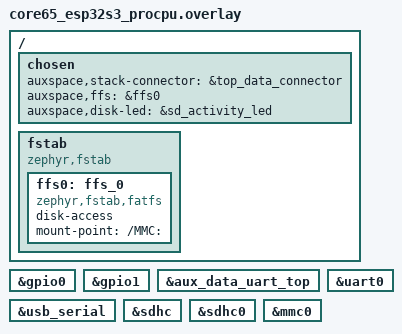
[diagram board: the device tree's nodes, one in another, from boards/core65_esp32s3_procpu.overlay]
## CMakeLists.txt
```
#-------------------------------------------------------------------------------
# telemetry_logger - AUX-Core ground-side telemetry recorder
#
# Copyright (c) 2026 Auxspace e.V.
# SPDX-License-Identifier: Apache-2.0

cmake_minimum_required(VERSION 3.20.0)

find_package(Zephyr REQUIRED HINTS $ENV{ZEPHYR_BASE})

project(telemetry_logger LANGUAGES C)

target_sources(app PRIVATE
	src/main.c
	src/link.c
	src/recorder.c
	)

target_sources_ifdef(CONFIG_TELEMETRY_LOGGER_SHELL app PRIVATE
	src/tlog_shell.c
	)
```

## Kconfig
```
# Copyright (c) 2026 Auxspace e.V.
# SPDX-License-Identifier: Apache-2.0
#
# Application Kconfig entry point for telemetry_logger, the AUX-Core
# ground-side recorder for frames delivered by an abby receiver.

menu "Zephyr"

source "Kconfig.zephyr"

endmenu

module = TELEMETRY_LOGGER
module-str = TELEMETRY_LOGGER
source "subsys/logging/Kconfig.template.log_config"

menu "telemetry_logger - ground-side telemetry recorder"

menu "Stack link"

config TELEMETRY_LOGGER_RX_RING_SIZE
	int "Receive ring buffer size (bytes)"
	default 1024
	help
	  Buffers bytes between the UART interrupt and the frame parser.
	  Overruns are counted and reported by "tlog status".

config TELEMETRY_LOGGER_LINK_STACK_SIZE
	int "Link parser thread stack size (bytes)"
	default 2048

config TELEMETRY_LOGGER_LINK_THREAD_PRIORITY
	int "Link parser thread priority"
	default 7
	help
	  Above the recorder thread, so parsing keeps up with the UART
	  while the SD card stalls on a write or a sync.

endmenu # Stack link

menu "Recorder"

config TELEMETRY_LOGGER_DIR
	string "Directory the recordings are written to"
	default "/MMC:/RX"
	help
	  Created if missing. Each recording session gets the next free
	  index in here: RX_<n>.BIN holds the frames verbatim, RX_<n>.CSV
	  the decoded rows.

config TELEMETRY_LOGGER_CSV
	bool "Also write a decoded CSV next to the raw recording"
	default y
	select REQUIRES_FLOAT_PRINTF
	help
	  One row per frame with the receive time and the SM_UPDATE /
	  STATUS fields decoded. The .BIN file is the authoritative
	  record either way; the CSV only saves a decoding step when
	  reading the card on a laptop.

config TELEMETRY_LOGGER_QUEUE_DEPTH
	int "Frames buffered between the parser and the SD card"
	default 16
	range 2 256
	help
	  Each slot holds one maximum-size frame (~270 bytes). At the
	  brain board's 2 Hz downlink 16 slots ride out an 8 s card
	  stall. Frames that find the queue full are counted as dropped.

config TELEMETRY_LOGGER_SYNC_INTERVAL_MS
	int "Maximum time between file syncs (ms)"
	default 1000
	range 100 60000
	help
	  Bounds how much of the recording a power cut can take with it.
	  FAT only commits the directory entry's size on sync, so data
	  written after the last sync is lost on a hard power-off.

config TELEMETRY_LOGGER_RETRY_MS
	int "Retry interval while no recording is open (ms)"
	default 2000
	range 100 60000
	help
	  With no card, an unformatted card or after a write error the
	  recorder re-mounts and opens a fresh recording at this interval,
	  so a card inserted after boot is picked up without a reset.

config TELEMETRY_LOGGER_WRITER_STACK_SIZE
	int "Recorder thread stack size (bytes)"
	default 4096

config TELEMETRY_LOGGER_WRITER_THREAD_PRIORITY
	int "Recorder thread priority"
	default 9

endmenu # Recorder

config TELEMETRY_LOGGER_HEARTBEAT_SEC
	int "Heartbeat interval (s)"
	default 30
	range 1 3600

config TELEMETRY_LOGGER_HEARTBEAT_LOG
	bool "Log counters on each heartbeat"
	default y

config TELEMETRY_LOGGER_SHELL
	bool "tlog shell commands"
	depends on SHELL
	default y if SHELL
	help
	  Registers the "tlog" command tree: status, and test to record a
	  synthetic frame so the SD path can be proven without a receiver
	  attached.

endmenu
```

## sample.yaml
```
# Copyright (c) 2026 Auxspace e.V.
# SPDX-License-Identifier: Apache-2.0
#
# Lets Twister build the application in CI. Build checks only: proving the
# recorder end to end needs an abby receiver and an SD card.
sample:
  description: AUX-Core recorder for telemetry frames from an abby receiver
  name: telemetry_logger
common:
  build_only: true
  platform_allow:
    - core65@1/esp32s3/procpu
  integration_platforms:
    - core65@1/esp32s3/procpu
tests:
  telemetry_logger.default.sysbuild:
    sysbuild: true
  telemetry_logger.debug.sysbuild:
    sysbuild: true
    extra_overlay_confs:
      - debug.conf
  telemetry_logger.no_csv:
    extra_configs:
      - CONFIG_TELEMETRY_LOGGER_CSV=n
  telemetry_logger.no_shell:
    extra_configs:
      - CONFIG_SHELL=n
      - CONFIG_TELEMETRY_LOGGER_SHELL=n
      - CONFIG_FILE_SYSTEM_SHELL=n
```

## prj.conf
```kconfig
# Copyright (c) 2026 Auxspace e.V.
# SPDX-License-Identifier: Apache-2.0

CONFIG_BOOT_BANNER_STRING="Booting AURORA"

CONFIG_LOG=y
CONFIG_LOG_DEFAULT_LEVEL=3

CONFIG_CONSOLE=y
CONFIG_SERIAL=y

# The stack-link receiver drains the UART from its interrupt.
CONFIG_UART_INTERRUPT_DRIVEN=y

CONFIG_CRC=y

CONFIG_FILE_SYSTEM=y

# Bring-up shell: "tlog status", "tlog test", and "fs" to pull recordings
# off the card without removing it.
CONFIG_SHELL=y
CONFIG_TELEMETRY_LOGGER_SHELL=y
CONFIG_FILE_SYSTEM_SHELL=y
CONFIG_SHELL_LOG_BACKEND=n

CONFIG_STACK_SENTINEL=y
CONFIG_ASSERT=y
```

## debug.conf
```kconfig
# Copyright (c) 2026 Auxspace e.V.
# SPDX-License-Identifier: Apache-2.0
#
# Extra overlay for bench work:
#   west build -b core65/esp32s3/procpu telemetry_logger -- -DEXTRA_CONF_FILE=debug.conf

CONFIG_TELEMETRY_LOGGER_LOG_LEVEL_DBG=y
CONFIG_LOG_MODE_IMMEDIATE=y

CONFIG_RESET_ON_FATAL_ERROR=y
CONFIG_HW_STACK_PROTECTION=y
CONFIG_INIT_STACKS=y
CONFIG_THREAD_STACK_INFO=y

CONFIG_THREAD_NAME=y
CONFIG_THREAD_ANALYZER=y
CONFIG_THREAD_ANALYZER_USE_PRINTK=y
CONFIG_THREAD_ANALYZER_AUTO=n
```

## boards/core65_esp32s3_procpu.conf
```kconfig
# Copyright (c) 2026 Auxspace e.V.
# SPDX-License-Identifier: Apache-2.0

CONFIG_USE_DT_CODE_PARTITION=y
CONFIG_GPIO=y
CONFIG_UART_CONSOLE=y

# SD card (native SDHC, FAT)
CONFIG_DISK_ACCESS=y
CONFIG_FAT_FILESYSTEM_ELM=y
CONFIG_FS_FATFS_LFN=y
CONFIG_FS_FATFS_LFN_MODE_HEAP=y
CONFIG_FS_FATFS_CUSTOM_MOUNT_POINT_COUNT=1
CONFIG_FS_FATFS_CUSTOM_MOUNT_POINTS="MMC"
CONFIG_HEAP_MEM_POOL_SIZE=16384

# SD activity LED.
# Only the notify core and the disk LED:
# the buzzer and PWM LED backends signal flight states and need the state machine.
CONFIG_AURORA_NOTIFY=y
CONFIG_AURORA_NOTIFY_DISK_LED=y

# Stacks
CONFIG_ISR_STACK_SIZE=4096
CONFIG_LOG_PROCESS_THREAD_STACK_SIZE=4096
CONFIG_SHELL_STACK_SIZE=4096
CONFIG_SYSTEM_WORKQUEUE_STACK_SIZE=4096
```

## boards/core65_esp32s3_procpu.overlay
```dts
/*
 * Copyright (c) 2026 Auxspace e.V.
 * SPDX-License-Identifier: Apache-2.0
 */

/ {
	chosen {
		/*
		 * Which AUX-Stack data connector the abby receiver is on.
		 * telemetry_logger reads the UART out of this node's uart-bus
		 * phandle, so it names no board-specific peripheral.
		 *
		 * Use bottom_data_connector instead if AUX-Tel is stacked
		 * below.
		 */
		auxspace,stack-connector = &top_data_connector;
		auxspace,ffs = &ffs0;
		auxspace,disk-led = &sd_activity_led;
	};

	fstab {
		compatible = "zephyr,fstab";

		/* Not automounted: the recorder owns the mount, so it can
		 * unmount after a write error and pick up a swapped card.
		 */
		ffs0: ffs_0 {
			compatible = "zephyr,fstab,fatfs";
			disk-access;
			mount-point = "/MMC:";
		};
	};
};

&gpio0 {
	status = "okay";
};

&gpio1 {
	status = "okay";
};

&aux_data_uart_top {
	status = "okay";
};

&uart0 {
	status = "okay";
};

&usb_serial {
	status = "okay";
};

&sdhc {
	status = "okay";
};

&sdhc0 {
	status = "okay";
};

&mmc0 {
	status = "okay";
};
```

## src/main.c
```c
/*
 * Copyright (c) 2026 Auxspace e.V.
 * SPDX-License-Identifier: Apache-2.0
 *
 * telemetry_logger - the AUX-Core ground-side telemetry recorder.
 *
 * On the ground an AUX-Tel running abby in its receive role turns the
 * LoRa downlink back into the telemetry wire byte stream on the AUX-Stack
 * data connector. This application is what sits on the other side of that
 * connector: an AUX-Core that parses the stream and writes every valid
 * frame to the SD card, unconditionally - from boot until power is cut,
 * with no state machine, arming or flight window deciding what is kept.
 *
 * It flies nothing and reads no sensors; sensor_board does that on the
 * vehicle. The two transports live in link.c (the stack UART) and
 * recorder.c (the SD card).
 */

#include <zephyr/kernel.h>
#include <zephyr/logging/log.h>

#include <zephyr/app_version.h>

#include "link.h"
#include "recorder.h"

LOG_MODULE_REGISTER(tlog, CONFIG_TELEMETRY_LOGGER_LOG_LEVEL);

int main(void)
{
	int rc;

	LOG_INF("telemetry_logger %s on %s", APP_VERSION_STRING,
		CONFIG_BOARD_TARGET);

	/* Sink before source: the recorder has to be taking frames before
	 * the link starts delivering them. It does not wait for the card,
	 * so a board without one still parses and counts.
	 */
	rc = recorder_init();
	if (rc) {
		LOG_ERR("recorder init failed (%d)", rc);
		return rc;
	}

	rc = link_init();
	if (rc) {
		LOG_ERR("stack link init failed (%d)", rc);
		return rc;
	}

	/* Everything runs in the link and recorder threads. */
	while (1) {
		k_sleep(K_SECONDS(CONFIG_TELEMETRY_LOGGER_HEARTBEAT_SEC));

		if (IS_ENABLED(CONFIG_TELEMETRY_LOGGER_HEARTBEAT_LOG)) {
			struct link_stats ls;
			struct recorder_stats rs;

			link_get_stats(&ls);
			recorder_get_stats(&rs);

			LOG_INF("uart rx %u frames (%u crc, %u overrun) | "
				"sd %u recorded, %u unrecorded, %u dropped, "
				"%u err | %s",
				ls.frames, ls.crc_errs, ls.overruns,
				rs.recorded, rs.unrecorded, rs.dropped,
				rs.write_errs, rs.open ? "recording" : "NO CARD");
		}
	}

	return 0;
}
```

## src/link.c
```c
/*
 * Copyright (c) 2026 Auxspace e.V.
 * SPDX-License-Identifier: Apache-2.0
 *
 * The AUX-Stack data-connector UART: the wire from the abby receiver.
 *
 * Drains the UART and reassembles telemetry wire frames out of the byte
 * stream. Every frame that passes its CRC goes to the recorder verbatim;
 * nothing here looks at the payload, so a packet type this firmware has
 * never heard of is still recorded.
 */

#include <zephyr/device.h>
#include <zephyr/devicetree.h>
#include <zephyr/drivers/uart.h>
#include <zephyr/kernel.h>
#include <zephyr/logging/log.h>
#include <zephyr/sys/atomic.h>
#include <zephyr/sys/byteorder.h>
#include <zephyr/sys/ring_buffer.h>

#include <aurora/lib/telemetry/wire.h>

#include "link.h"
#include "recorder.h"

LOG_MODULE_REGISTER(tlog_link, CONFIG_TELEMETRY_LOGGER_LOG_LEVEL);

/* The connector binding carries the phandle of whichever UART the board
 * wires to the data connector's TXD/RXD pins, so this file never names a
 * board-specific peripheral.
 */
#define STACK_CONNECTOR DT_CHOSEN(auxspace_stack_connector)

BUILD_ASSERT(DT_NODE_EXISTS(STACK_CONNECTOR),
	     "Set the auxspace,stack-connector chosen node to an "
	     "auxspaceev,aux-stack-data-connector node");
BUILD_ASSERT(DT_NODE_HAS_PROP(STACK_CONNECTOR, uart_bus),
	     "The chosen auxspace,stack-connector has no uart-bus property");

#define STACK_UART_NODE DT_PHANDLE(STACK_CONNECTOR, uart_bus)

BUILD_ASSERT(DT_NODE_HAS_STATUS_OKAY(STACK_UART_NODE),
	     "The stack connector's uart-bus is disabled");

static const struct device *const stack_uart = DEVICE_DT_GET(STACK_UART_NODE);

static struct {
	atomic_t frames;
	atomic_t crc_errs;
	atomic_t overruns;
} stats;

RING_BUF_DECLARE(rx_rb, CONFIG_TELEMETRY_LOGGER_RX_RING_SIZE);
static K_SEM_DEFINE(rx_sem, 0, 1);

static void uart_isr(const struct device *dev, void *user_data)
{
	uint8_t buf[32];

	ARG_UNUSED(user_data);

	/* uart_irq_update() returns void here; it only latches the
	 * pending-interrupt state that the rx_ready query below reads.
	 */
	uart_irq_update(dev);

	while (uart_irq_rx_ready(dev)) {
		int n = uart_fifo_read(dev, buf, sizeof(buf));

		if (n <= 0) {
			break;
		}

		uint32_t put = ring_buf_put(&rx_rb, buf, (uint32_t)n);

		if (put < (uint32_t)n) {
			atomic_add(&stats.overruns, (uint32_t)n - put);
		}
		k_sem_give(&rx_sem);
	}
}

/* Frame reassembly state. Only touched by the parser thread.
 *
 * Same parser as abby's relay role, and with the same property: a
 * truncated frame leaves the parser mid-payload, so it eats a frame's
 * worth of the following bytes before it can look for a sync pair again,
 * and the frame after a truncation can be lost. abby writes whole frames
 * under a mutex, so in practice this only happens across a cable unplug.
 */
enum parse_state {
	P_MAGIC0 = 0,
	P_MAGIC1,
	P_TYPE,
	P_LEN,
	P_PAYLOAD,
	P_CRC_LO,
	P_CRC_HI,
};

static enum parse_state pstate;
static uint8_t frame[AURORA_TELEMETRY_WIRE_MAX_FRAME];
static uint16_t fidx;
static uint8_t payload_len;

static void frame_complete(void)
{
	uint16_t want = telemetry_wire_crc(frame, payload_len);
	uint16_t got = sys_get_le16(
		&frame[AURORA_TELEMETRY_WIRE_HDR_LEN + payload_len]);

	if (want != got) {
		atomic_inc(&stats.crc_errs);
		LOG_WRN("CRC mismatch (want %04x got %04x), resyncing",
			want, got);
		return;
	}

	atomic_inc(&stats.frames);
	LOG_DBG("frame type %u, %u byte payload", frame[2], payload_len);

	(void)recorder_submit(frame, fidx);
}

static void parse_byte(uint8_t b)
{
	switch (pstate) {
	case P_MAGIC0:
		if (b == AURORA_TELEMETRY_WIRE_MAGIC0) {
			frame[0] = b;
			pstate = P_MAGIC1;
		}
		break;

	case P_MAGIC1:
		if (b == AURORA_TELEMETRY_WIRE_MAGIC1) {
			frame[1] = b;
			pstate = P_TYPE;
		} else if (b != AURORA_TELEMETRY_WIRE_MAGIC0) {
			/* Not a sync pair; but a repeated magic0 could still
			 * be the real start, so only give up otherwise.
			 */
			pstate = P_MAGIC0;
		}
		break;

	case P_TYPE:
		frame[2] = b;
		pstate = P_LEN;
		break;

	case P_LEN:
		frame[3] = b;
		payload_len = b;
		fidx = AURORA_TELEMETRY_WIRE_HDR_LEN;
		pstate = (payload_len == 0) ? P_CRC_LO : P_PAYLOAD;
		break;

	case P_PAYLOAD:
		frame[fidx++] = b;
		if (fidx == (uint16_t)AURORA_TELEMETRY_WIRE_HDR_LEN +
				    payload_len) {
			pstate = P_CRC_LO;
		}
		break;

	case P_CRC_LO:
		frame[fidx++] = b;
		pstate = P_CRC_HI;
		break;

	case P_CRC_HI:
		frame[fidx++] = b;
		frame_complete();
		pstate = P_MAGIC0;
		break;
	}
}

static void link_thread(void *a, void *b, void *c)
{
	ARG_UNUSED(a);
	ARG_UNUSED(b);
	ARG_UNUSED(c);

	while (1) {
		(void)k_sem_take(&rx_sem, K_FOREVER);

		uint8_t byte;

		while (ring_buf_get(&rx_rb, &byte, 1) == 1) {
			parse_byte(byte);
		}
	}
}

/* Started by link_init() rather than at boot, so no frame can reach the
 * recorder before recorder_init() has run.
 */
K_THREAD_DEFINE(tlog_link_tid, CONFIG_TELEMETRY_LOGGER_LINK_STACK_SIZE,
		link_thread, NULL, NULL, NULL,
		CONFIG_TELEMETRY_LOGGER_LINK_THREAD_PRIORITY, 0, SYS_FOREVER_MS);

void link_get_stats(struct link_stats *out)
{
	if (!out) {
		return;
	}
	out->frames = (uint32_t)atomic_get(&stats.frames);
	out->crc_errs = (uint32_t)atomic_get(&stats.crc_errs);
	out->overruns = (uint32_t)atomic_get(&stats.overruns);
}

int link_init(void)
{
	if (!device_is_ready(stack_uart)) {
		LOG_ERR("stack UART %s not ready", stack_uart->name);
		return -ENODEV;
	}

	k_thread_start(tlog_link_tid);

	uart_irq_callback_user_data_set(stack_uart, uart_isr, NULL);
	uart_irq_rx_enable(stack_uart);

	LOG_INF("stack link up on %s, listening for frames",
		stack_uart->name);

	return 0;
}
```

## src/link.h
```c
/*
 * Copyright (c) 2026 Auxspace e.V.
 * SPDX-License-Identifier: Apache-2.0
 */

#ifndef TELEMETRY_LOGGER_LINK_H_
#define TELEMETRY_LOGGER_LINK_H_

#include <stdint.h>

/** @brief Counters for the AUX-Stack connector UART. */
struct link_stats {
	uint32_t frames;    /**< Frames accepted (magic and CRC good). */
	uint32_t crc_errs;  /**< Frames discarded on a CRC mismatch. */
	uint32_t overruns;  /**< Bytes dropped because the ring buffer was full. */
};

/**
 * @brief Bring up the stack UART and start parsing frames.
 *
 * Every frame that passes its CRC goes to the recorder, so call it only
 * once the recorder is up.
 *
 * @retval 0 on success.
 * @retval -ENODEV if the UART is not ready.
 */
int link_init(void);

/** @brief Snapshot the link counters. */
void link_get_stats(struct link_stats *out);

#endif /* TELEMETRY_LOGGER_LINK_H_ */
```

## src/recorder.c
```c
/*
 * Copyright (c) 2026 Auxspace e.V.
 * SPDX-License-Identifier: Apache-2.0
 *
 * The SD-card recorder.
 *
 * Every frame the link hands over is written, unconditionally: there is
 * no state machine, no arming and no flight window here, because on the
 * ground the interesting part of a flight is exactly the part a gate
 * would have to guess at. The recorder starts at boot and keeps going
 * until power is cut.
 *
 * A recording is two files sharing an index in CONFIG_TELEMETRY_LOGGER_DIR:
 *
 *   RX_<n>.BIN  the frames verbatim, back to back - the same byte stream
 *               abby put on the stack UART, so any tool that parses the
 *               wire format parses the file. This is the authoritative
 *               record.
 *   RX_<n>.CSV  one decoded row per frame, prefixed with the time the
 *               frame arrived here. Convenience only.
 *
 * The recorder owns the mount. With no card, an unreadable card or after
 * a write error it unmounts, retries every CONFIG_TELEMETRY_LOGGER_RETRY_MS
 * and opens a fresh index rather than appending to a file whose tail may
 * be damaged. Frames that arrive with nothing open are counted, not
 * queued: once the queue is full the freshest frames would be the ones
 * lost, which is the wrong way round for telemetry.
 */

#include <stdio.h>
#include <string.h>

#include <zephyr/devicetree.h>
#include <zephyr/fs/fs.h>
#include <zephyr/kernel.h>
#include <zephyr/logging/log.h>
#include <zephyr/sys/atomic.h>

#include <aurora/lib/disk_led.h>
#include <aurora/lib/telemetry/wire.h>

#include "recorder.h"

LOG_MODULE_REGISTER(tlog_recorder, CONFIG_TELEMETRY_LOGGER_LOG_LEVEL);

#if !DT_HAS_CHOSEN(auxspace_ffs)
#error "Set the auxspace,ffs chosen node to the zephyr,fstab entry to record to"
#endif

#define FS_NODE DT_CHOSEN(auxspace_ffs)

FS_FSTAB_DECLARE_ENTRY(FS_NODE);

#define FILE_PREFIX "RX_"
#define PATH_MAX_LEN 64

struct rx_frame {
	int64_t rx_ms;
	uint16_t len;
	uint8_t data[AURORA_TELEMETRY_WIRE_MAX_FRAME];
};

K_MSGQ_DEFINE(frame_q, sizeof(struct rx_frame),
	      CONFIG_TELEMETRY_LOGGER_QUEUE_DEPTH, 4);

static struct {
	atomic_t recorded;
	atomic_t dropped;
	atomic_t unrecorded;
	atomic_t write_errs;
	atomic_t sessions;
	atomic_t open;
	atomic_t index;
} stats;

/* Only touched by the recorder thread, apart from the snapshot in
 * recorder_get_stats(), which may read a torn value on a 32-bit core and
 * is only ever printed.
 */
static uint64_t bin_bytes;

static bool mounted;
static struct fs_file_t bin_file;
#if defined(CONFIG_TELEMETRY_LOGGER_CSV)
static struct fs_file_t csv_file;
#endif

int recorder_submit(const uint8_t *frame, size_t len)
{
	struct rx_frame f;

	if (!frame || len == 0 || len > sizeof(f.data)) {
		return -EINVAL;
	}

	f.rx_ms = k_uptime_get();
	f.len = (uint16_t)len;
	memcpy(f.data, frame, len);

	if (k_msgq_put(&frame_q, &f, K_NO_WAIT) != 0) {
		atomic_inc(&stats.dropped);
		return -ENOBUFS;
	}

	return 0;
}

/* ---- mount and session ------------------------------------------------ */

static int mount_card(void)
{
	struct fs_mount_t *mp = &FS_FSTAB_ENTRY(FS_NODE);
	int rc;

	if (mounted) {
		return 0;
	}

	rc = fs_mount(mp);
	if (rc == -EBUSY) {
		/* Automounted at boot. */
		rc = 0;
	}
	if (rc) {
		return rc;
	}

	mounted = true;
	LOG_INF("%s mounted", mp->mnt_point);
	return 0;
}

static void unmount_card(void)
{
	if (!mounted) {
		return;
	}

	/* Unmounting deinitialises the disk, so the next mount re-probes it
	 * and picks up a card that was swapped in the meantime.
	 */
	(void)fs_unmount(&FS_FSTAB_ENTRY(FS_NODE));
	mounted = false;
}

static int ensure_dir(void)
{
	struct fs_dirent ent;
	int rc = fs_stat(CONFIG_TELEMETRY_LOGGER_DIR, &ent);

	if (rc == 0) {
		return (ent.type == FS_DIR_ENTRY_DIR) ? 0 : -ENOTDIR;
	}
	if (rc != -ENOENT) {
		return rc;
	}

	return fs_mkdir(CONFIG_TELEMETRY_LOGGER_DIR);
}

/* Next free index: one past the highest RX_<n>.BIN already in the
 * directory, so a recording is never overwritten and a gap left by a
 * deleted file is not reused.
 */
static int next_index(uint32_t *out)
{
	struct fs_dir_t dir;
	struct fs_dirent ent;
	uint32_t next = 0;
	int rc;

	fs_dir_t_init(&dir);

	rc = fs_opendir(&dir, CONFIG_TELEMETRY_LOGGER_DIR);
	if (rc) {
		return rc;
	}

	while ((rc = fs_readdir(&dir, &ent)) == 0 && ent.name[0] != '\0') {
		unsigned int n;
		char ext[4];

		if (ent.type != FS_DIR_ENTRY_FILE) {
			continue;
		}
		if (sscanf(ent.name, FILE_PREFIX "%u.%3s", &n, ext) == 2 &&
		    strcmp(ext, "BIN") == 0 && n + 1 > next) {
			next = n + 1;
		}
	}

	(void)fs_closedir(&dir);

	*out = next;
	return rc;
}

static int open_file(struct fs_file_t *file, uint32_t index, const char *ext)
{
	char path[PATH_MAX_LEN];

	snprintf(path, sizeof(path), "%s/" FILE_PREFIX "%04u.%s",
		 CONFIG_TELEMETRY_LOGGER_DIR, index, ext);

	fs_file_t_init(file);

	/* No FS_O_TRUNC: the index was free a moment ago, and if it somehow
	 * is not, appending loses less than truncating would.
	 */
	int rc = fs_open(file, path, FS_O_CREATE | FS_O_WRITE | FS_O_APPEND);

	if (rc) {
		LOG_ERR("open %s failed (%d)", path, rc);
	}
	return rc;
}

#if defined(CONFIG_TELEMETRY_LOGGER_CSV)
static const char csv_header[] =
	"rx_ms,type,len,tx_ms,state,armed,sm_type,flags,"
	"altitude,acceleration,accel_vert,velocity,yaw,pitch,roll\n";
#endif

static void session_close(void)
{
	if (!atomic_get(&stats.open)) {
		return;
	}

	(void)fs_close(&bin_file);
#if defined(CONFIG_TELEMETRY_LOGGER_CSV)
	(void)fs_close(&csv_file);
#endif
	atomic_set(&stats.open, 0);
}

static int session_open(void)
{
	uint32_t index;
	int rc;

	rc = mount_card();
	if (rc) {
		return rc;
	}

	rc = ensure_dir();
	if (rc) {
		LOG_ERR("cannot create %s (%d)", CONFIG_TELEMETRY_LOGGER_DIR, rc);
		return rc;
	}

	rc = next_index(&index);
	if (rc) {
		LOG_ERR("cannot list %s (%d)", CONFIG_TELEMETRY_LOGGER_DIR, rc);
		return rc;
	}

	rc = open_file(&bin_file, index, "BIN");
	if (rc) {
		return rc;
	}

#if defined(CONFIG_TELEMETRY_LOGGER_CSV)
	rc = open_file(&csv_file, index, "CSV");
	if (rc) {
		(void)fs_close(&bin_file);
		return rc;
	}

	ssize_t n = fs_write(&csv_file, csv_header, sizeof(csv_header) - 1);

	if (n != (ssize_t)(sizeof(csv_header) - 1)) {
		(void)fs_close(&bin_file);
		(void)fs_close(&csv_file);
		return (n < 0) ? (int)n : -EIO;
	}
#endif

	bin_bytes = 0;
	atomic_set(&stats.index, (atomic_val_t)index);
	atomic_inc(&stats.sessions);
	atomic_set(&stats.open, 1);

	LOG_INF("recording to %s/" FILE_PREFIX "%04u.BIN",
		CONFIG_TELEMETRY_LOGGER_DIR, index);
	return 0;
}

/* ---- writing ------------------------------------------------------------ */

#if defined(CONFIG_TELEMETRY_LOGGER_CSV)
/* Decode only frames whose length matches the layout exactly: a payload
 * that is longer or shorter than its type implies came from a firmware
 * with a different wire revision, and decoding it by offset would print
 * numbers that look plausible and are wrong. It still gets a row, with
 * only the framing filled in, and is in the .BIN in full.
 */
static int format_row(const struct rx_frame *f, char *buf, size_t buf_sz)
{
	const uint8_t type = f->data[2];
	const uint8_t len = f->data[3];
	const uint8_t *payload = &f->data[AURORA_TELEMETRY_WIRE_HDR_LEN];

	if (type == AURORA_TELEMETRY_WIRE_TYPE_SM_UPDATE &&
	    len == sizeof(struct telemetry_wire_sm_update)) {
		struct telemetry_wire_sm_update u;

		memcpy(&u, payload, sizeof(u));
		return snprintf(buf, buf_sz,
				"%lld,%u,%u,%u,%u,%u,%u,,"
				"%.3f,%.3f,%.3f,%.3f,%.2f,%.2f,%.2f\n",
				(long long)f->rx_ms, type, len,
				u.timestamp_ms, u.state, u.armed, u.sm_type,
				u.altitude, u.acceleration, u.accel_vert,
				u.velocity, u.orientation[0],
				u.orientation[1], u.orientation[2]);
	}

	if (type == AURORA_TELEMETRY_WIRE_TYPE_STATUS &&
	    len == sizeof(struct telemetry_wire_status)) {
		struct telemetry_wire_status s;

		memcpy(&s, payload, sizeof(s));
		return snprintf(buf, buf_sz,
				"%lld,%u,%u,%u,%u,%u,%u,0x%02x,,,,,,,\n",
				(long long)f->rx_ms, type, len,
				s.timestamp_ms, s.state,
				(s.flags & AURORA_TELEMETRY_WIRE_STATUS_ARMED) ? 1 : 0,
				s.sm_type, s.flags);
	}

	return snprintf(buf, buf_sz, "%lld,%u,%u,,,,,,,,,,,,\n",
			(long long)f->rx_ms, type, len);
}
#endif /* CONFIG_TELEMETRY_LOGGER_CSV */

static int write_all(struct fs_file_t *file, const void *data, size_t len)
{
	ssize_t n = fs_write(file, data, len);

	if (n < 0) {
		return (int)n;
	}
	return (n == (ssize_t)len) ? 0 : -ENOSPC;
}

static int record(const struct rx_frame *f)
{
	int rc = write_all(&bin_file, f->data, f->len);

	if (rc) {
		return rc;
	}
	bin_bytes += f->len;

#if defined(CONFIG_TELEMETRY_LOGGER_CSV)
	char row[192];
	int n = format_row(f, row, sizeof(row));

	if (n > 0) {
		rc = write_all(&csv_file, row, MIN((size_t)n, sizeof(row) - 1));
		if (rc) {
			return rc;
		}
	}
#endif

	disk_led_activity();
	return 0;
}

static int sync_files(void)
{
	int rc = fs_sync(&bin_file);

#if defined(CONFIG_TELEMETRY_LOGGER_CSV)
	int rc_csv = fs_sync(&csv_file);

	if (rc == 0) {
		rc = rc_csv;
	}
#endif
	return rc;
}

/* Drop the recording after a failed write or sync. The next attempt opens
 * a fresh index on a re-probed card instead of appending to a file whose
 * tail is in an unknown state.
 */
static void write_failed(int rc)
{
	atomic_inc(&stats.write_errs);
	LOG_ERR("write to " FILE_PREFIX "%04u failed (%d), reopening",
		(uint32_t)atomic_get(&stats.index), rc);
	session_close();
	unmount_card();
}

static void recorder_thread(void *a, void *b, void *c)
{
	ARG_UNUSED(a);
	ARG_UNUSED(b);
	ARG_UNUSED(c);

	struct rx_frame f;
	int64_t next_open = 0;
	int64_t last_sync = 0;
	bool dirty = false;
	bool warned = false;

	while (1) {
		int rc = k_msgq_get(&frame_q, &f,
				    K_MSEC(CONFIG_TELEMETRY_LOGGER_SYNC_INTERVAL_MS));
		int64_t now = k_uptime_get();

		if (!atomic_get(&stats.open) && now >= next_open) {
			int orc = session_open();

			if (orc == 0) {
				warned = false;
				last_sync = now;
			} else {
				unmount_card();
				if (!warned) {
					LOG_WRN("no recording open (%d), retrying "
						"every %d ms", orc,
						CONFIG_TELEMETRY_LOGGER_RETRY_MS);
					warned = true;
				}
				next_open = now + CONFIG_TELEMETRY_LOGGER_RETRY_MS;
			}
		}

		if (rc == 0) {
			if (!atomic_get(&stats.open)) {
				atomic_inc(&stats.unrecorded);
			} else if ((rc = record(&f)) != 0) {
				write_failed(rc);
				next_open = now;
				dirty = false;
			} else {
				atomic_inc(&stats.recorded);
				dirty = true;
			}
		}

		if (dirty && now - last_sync >=
				     CONFIG_TELEMETRY_LOGGER_SYNC_INTERVAL_MS) {
			rc = sync_files();
			if (rc) {
				write_failed(rc);
				next_open = now;
			}
			dirty = false;
			last_sync = now;
		}
	}
}

K_THREAD_DEFINE(tlog_recorder_tid, CONFIG_TELEMETRY_LOGGER_WRITER_STACK_SIZE,
		recorder_thread, NULL, NULL, NULL,
		CONFIG_TELEMETRY_LOGGER_WRITER_THREAD_PRIORITY, 0, SYS_FOREVER_MS);

int recorder_init(void)
{
	k_thread_start(tlog_recorder_tid);
	return 0;
}

void recorder_get_stats(struct recorder_stats *out)
{
	if (!out) {
		return;
	}
	out->recorded = (uint32_t)atomic_get(&stats.recorded);
	out->dropped = (uint32_t)atomic_get(&stats.dropped);
	out->unrecorded = (uint32_t)atomic_get(&stats.unrecorded);
	out->write_errs = (uint32_t)atomic_get(&stats.write_errs);
	out->sessions = (uint32_t)atomic_get(&stats.sessions);
	out->open = atomic_get(&stats.open) != 0;
	out->index = (uint32_t)atomic_get(&stats.index);
	out->bytes = bin_bytes;
}
```

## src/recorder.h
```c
/*
 * Copyright (c) 2026 Auxspace e.V.
 * SPDX-License-Identifier: Apache-2.0
 */

#ifndef TELEMETRY_LOGGER_RECORDER_H_
#define TELEMETRY_LOGGER_RECORDER_H_

#include <stdbool.h>
#include <stddef.h>
#include <stdint.h>

/** @brief Counters for the SD-card recorder. */
struct recorder_stats {
	uint32_t recorded;   /**< Frames written to the open recording. */
	uint32_t dropped;    /**< Frames that found the queue full. */
	uint32_t unrecorded; /**< Frames that arrived with no recording open. */
	uint32_t write_errs; /**< Write or sync failures (each closes the file). */
	uint32_t sessions;   /**< Recordings opened since boot. */
	bool open;           /**< A recording is open right now. */
	uint32_t index;      /**< Index of the open (or last) recording. */
	uint64_t bytes;      /**< Bytes written to the open recording's .BIN. */
};

/**
 * @brief Start the recorder.
 *
 * Never fails on a missing card: the recorder thread keeps retrying in
 * the background, and frames that arrive meanwhile are counted as
 * unrecorded.
 *
 * @retval 0 always.
 */
int recorder_init(void);

/**
 * @brief Hand one validated frame to the recorder.
 *
 * Never blocks; safe from the link parser thread.
 *
 * @param frame Frame bytes, starting at magic0.
 * @param len   Frame length in bytes.
 *
 * @retval 0 on success.
 * @retval -EINVAL if @p frame is NULL, or @p len is zero or too long.
 * @retval -ENOBUFS if the queue is full; the frame is counted as dropped.
 */
int recorder_submit(const uint8_t *frame, size_t len);

/** @brief Snapshot the recorder counters. */
void recorder_get_stats(struct recorder_stats *out);

#endif /* TELEMETRY_LOGGER_RECORDER_H_ */
```

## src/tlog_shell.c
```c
/*
 * Copyright (c) 2026 Auxspace e.V.
 * SPDX-License-Identifier: Apache-2.0
 *
 * "tlog" shell commands for bring-up.
 */

#include <zephyr/kernel.h>
#include <zephyr/shell/shell.h>

#include <aurora/lib/telemetry/wire.h>

#include "link.h"
#include "recorder.h"

static int cmd_status(const struct shell *sh, size_t argc, char **argv)
{
	struct link_stats ls;
	struct recorder_stats rs;

	ARG_UNUSED(argc);
	ARG_UNUSED(argv);

	link_get_stats(&ls);
	recorder_get_stats(&rs);

	shell_print(sh, "link:     %u frames, %u crc errors, %u bytes overrun",
		    ls.frames, ls.crc_errs, ls.overruns);
	if (rs.open) {
		shell_print(sh, "recorder: %s/RX_%04u.BIN, %llu bytes",
			    CONFIG_TELEMETRY_LOGGER_DIR, rs.index,
			    (unsigned long long)rs.bytes);
	} else {
		shell_print(sh, "recorder: no recording open, retrying every %d ms",
			    CONFIG_TELEMETRY_LOGGER_RETRY_MS);
	}
	shell_print(sh, "          %u recorded, %u unrecorded, %u dropped, "
		    "%u write errors, %u sessions",
		    rs.recorded, rs.unrecorded, rs.dropped, rs.write_errs,
		    rs.sessions);

	return 0;
}

/* Records a STATUS frame with every flag clear, so the SD path can be
 * proven with nothing on the stack connector. It goes through the same
 * queue as a received frame and lands in both files.
 */
static int cmd_test(const struct shell *sh, size_t argc, char **argv)
{
	struct telemetry_wire_status st = {
		.timestamp_ms = k_uptime_get_32(),
	};
	uint8_t frame[AURORA_TELEMETRY_WIRE_OVERHEAD + sizeof(st)];
	size_t len;
	int rc;

	ARG_UNUSED(argc);
	ARG_UNUSED(argv);

	len = telemetry_wire_finalise(frame, sizeof(frame),
				      AURORA_TELEMETRY_WIRE_TYPE_STATUS,
				      &st, sizeof(st));

	rc = recorder_submit(frame, len);
	if (rc) {
		shell_error(sh, "submit failed (%d)", rc);
		return rc;
	}

	shell_print(sh, "queued a %u byte STATUS frame", (unsigned int)len);
	return 0;
}

SHELL_STATIC_SUBCMD_SET_CREATE(tlog_cmds,
	SHELL_CMD(status, NULL, "Link and recorder counters", cmd_status),
	SHELL_CMD(test, NULL, "Record a synthetic STATUS frame", cmd_test),
	SHELL_SUBCMD_SET_END
);

SHELL_CMD_REGISTER(tlog, &tlog_cmds, "telemetry_logger commands", NULL);
```
